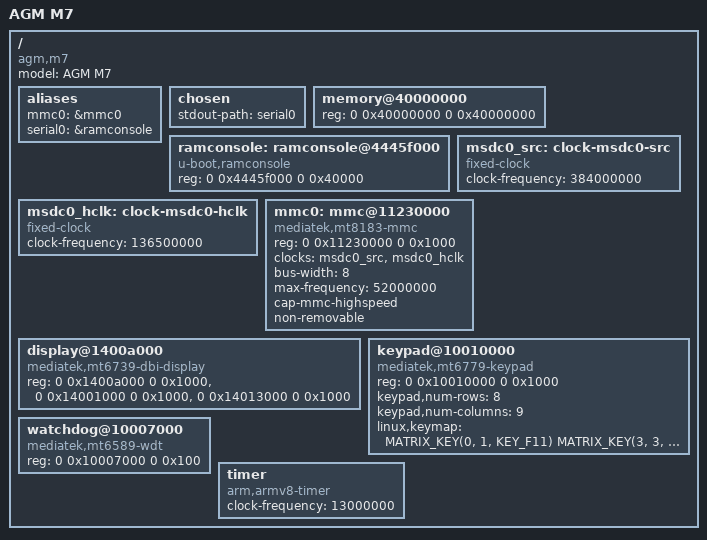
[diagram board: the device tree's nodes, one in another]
// SPDX-License-Identifier: GPL-2.0
/dts-v1/;

#include <dt-bindings/input/input.h>

/ {
	model = "AGM M7";
	compatible = "agm,m7", "mediatek,mt6739";
	#address-cells = <2>;
	#size-cells = <2>;

	aliases {
		mmc0 = &mmc0;
		serial0 = &ramconsole;
	};

	chosen {
		stdout-path = "serial0";
	};

	memory@40000000 {
		device_type = "memory";
		reg = <0 0x40000000 0 0x40000000>;
	};

	ramconsole: ramconsole@4445f000 {
		compatible = "u-boot,ramconsole";
		reg = <0 0x4445f000 0 0x40000>;
		bootph-all;
	};

	/* LK leaves the MSDC0 clocks running at these rates. */
	msdc0_src: clock-msdc0-src {
		compatible = "fixed-clock";
		#clock-cells = <0>;
		clock-frequency = <384000000>;
	};

	msdc0_hclk: clock-msdc0-hclk {
		compatible = "fixed-clock";
		#clock-cells = <0>;
		clock-frequency = <136500000>;
	};

	mmc0: mmc@11230000 {
		compatible = "mediatek,mt8183-mmc";
		reg = <0 0x11230000 0 0x1000>;
		clocks = <&msdc0_src>, <&msdc0_hclk>;
		clock-names = "source", "hclk";
		bus-width = <8>;
		max-frequency = <52000000>;
		cap-mmc-highspeed;
		non-removable;
	};

	display@1400a000 {
		compatible = "mediatek,mt6739-dbi-display";
		reg = <0 0x1400a000 0 0x1000>,
		      <0 0x14001000 0 0x1000>,
		      <0 0x14013000 0 0x1000>;
		reg-names = "ovl", "mutex", "dbi";
		bootph-all;
	};

	keypad@10010000 {
		compatible = "mediatek,mt6779-keypad";
		reg = <0 0x10010000 0 0x1000>;
		keypad,num-rows = <8>;
		keypad,num-columns = <9>;
		linux,keymap = <MATRIX_KEY(0, 1, KEY_F11)
				MATRIX_KEY(3, 3, KEY_MENU)
				MATRIX_KEY(3, 4, KEY_LEFT)
				MATRIX_KEY(3, 5, KEY_2)
				MATRIX_KEY(3, 6, KEY_8)
				MATRIX_KEY(4, 3, KEY_UP)
				MATRIX_KEY(4, 4, KEY_DOWN)
				MATRIX_KEY(4, 5, KEY_4)
				MATRIX_KEY(4, 6, KEY_9)
				MATRIX_KEY(5, 3, KEY_BACK)
				MATRIX_KEY(5, 4, KEY_RIGHT)
				MATRIX_KEY(5, 5, KEY_5)
				MATRIX_KEY(5, 6, KEY_NUMERIC_STAR)
				MATRIX_KEY(6, 3, KEY_ENTER)
				MATRIX_KEY(6, 4, KEY_3)
				MATRIX_KEY(6, 5, KEY_6)
				MATRIX_KEY(6, 6, KEY_0)
				MATRIX_KEY(7, 3, KEY_SEND)
				MATRIX_KEY(7, 4, KEY_1)
				MATRIX_KEY(7, 5, KEY_7)
				MATRIX_KEY(7, 6, KEY_NUMERIC_POUND)>;
	};

	watchdog@10007000 {
		compatible = "mediatek,mt6589-wdt";
		reg = <0 0x10007000 0 0x100>;
		bootph-all;
	};

	timer {
		compatible = "arm,armv8-timer";
		clock-frequency = <13000000>;
	};
};
